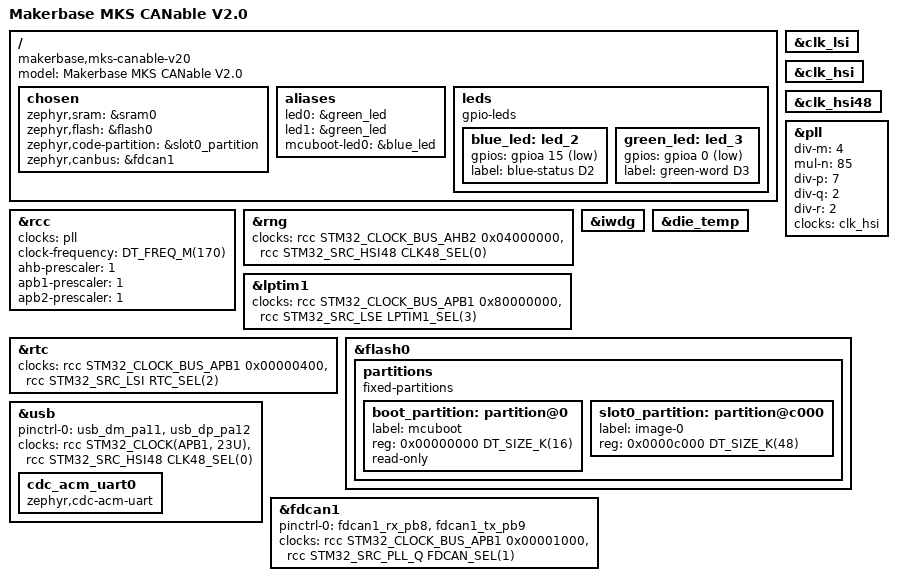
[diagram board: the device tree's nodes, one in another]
/*
 * Copyright (c) 2024 Alexander Kozhinov <ak.alexander.kozhinov@gmail.com>
 * SPDX-License-Identifier: Apache-2.0
 */

/dts-v1/;
#include <st/g4/stm32g431X8.dtsi>
#include <st/g4/stm32g431c(6-8-b)tx-pinctrl.dtsi>

/ {
	model = "Makerbase MKS CANable V2.0";
	compatible = "makerbase,mks-canable-v20";

	chosen {
		zephyr,sram = &sram0;
		zephyr,flash = &flash0;
		zephyr,code-partition = &slot0_partition;
		zephyr,canbus = &fdcan1;
	};

	aliases {
		led0 = &blue_led;
		led1 = &green_led;
		mcuboot-led0 = &blue_led;
	};

	leds: leds {
		compatible = "gpio-leds";
		blue_led: led_2 {
			gpios = <&gpioa 15 GPIO_ACTIVE_LOW>;
			label = "blue-status D2";
		};
		green_led: led_3 {
			gpios = <&gpioa 0 GPIO_ACTIVE_LOW>;
			label = "green-word D3";
		};
	};

	aliases {
		led0 = &green_led;
	};
};

&clk_lsi {
	status = "okay";
};

&clk_hsi {
	status = "okay";
};

&clk_hsi48 {
	status = "okay";
};

/* Adjust the pll for a SYSTEM Clock of 170MHz  */
&pll {
	div-m = <4>;
	mul-n = <85>;
	div-p = <7>;
	div-q = <2>;
	div-r = <2>;
	clocks = <&clk_hsi>;
	status = "okay";
};

&rcc {
	clocks = <&pll>;
	clock-frequency = <DT_FREQ_M(170)>;
	ahb-prescaler = <1>;
	apb1-prescaler = <1>;
	apb2-prescaler = <1>;
};

&rng {
	clocks = <&rcc STM32_CLOCK_BUS_AHB2 0x04000000>,
		 <&rcc STM32_SRC_HSI48 CLK48_SEL(0)>;
	status = "okay";
};

stm32_lp_tick_source: &lptim1 {
	clocks = <&rcc STM32_CLOCK_BUS_APB1 0x80000000>,
		 <&rcc STM32_SRC_LSE LPTIM1_SEL(3)>;
	status = "okay";
};

&rtc {
	status = "okay";
	clocks = <&rcc STM32_CLOCK_BUS_APB1 0x00000400>,
		 <&rcc STM32_SRC_LSI RTC_SEL(2)>;
};

&iwdg {
	status = "okay";
};

&die_temp {
	status = "okay";
};

&flash0 {
	partitions {
		compatible = "fixed-partitions";
		#address-cells = <1>;
		#size-cells = <1>;

		boot_partition: partition@0 {
			label = "mcuboot";
			reg = <0x00000000 DT_SIZE_K(16)>;
			read-only;
		};
		slot0_partition: partition@c000 {
			label = "image-0";
			reg = <0x0000c000 DT_SIZE_K(48)>;
		};
	};
};

zephyr_udc0: &usb {
	pinctrl-0 = <&usb_dm_pa11 &usb_dp_pa12>;
	pinctrl-names = "default";
	clocks = <&rcc STM32_CLOCK(APB1, 23U)>,
		 <&rcc STM32_SRC_HSI48 CLK48_SEL(0)>;
	status = "okay";

	cdc_acm_uart0: cdc_acm_uart0 {
		compatible = "zephyr,cdc-acm-uart";
	};
};

&fdcan1 {
	pinctrl-0 = <&fdcan1_rx_pb8 &fdcan1_tx_pb9>;
	pinctrl-names = "default";
	clocks = <&rcc STM32_CLOCK_BUS_APB1 0x00001000>,
		 <&rcc STM32_SRC_PLL_Q FDCAN_SEL(1)>;
	status = "okay";
};
